# VPAC0_PAR_VPAC_VISS0_S_VBUSP_VISS_FCP_FCC_VBUSP_FLEXCC register map
Vendor: Texas Instruments
Peripheral module from a debugger description file (folder J7ES).
Registers are 32-bit, access per field, reset 0x0 unless marked. A register's access mark holds for its fields unless they carry their own. Offsets are as the file gives them; lines under a group give offsets from that group; [hi:lo] are bit positions; {n}, {i} and the like mark numbered series; 'fields as' and 'values as' point back to an identical list; <NAME> marks a mode.

## VPAC0_PAR_VPAC_VISS0_S_VBUSP_VISS_FCP_FCC_VBUSP_FLEXCC
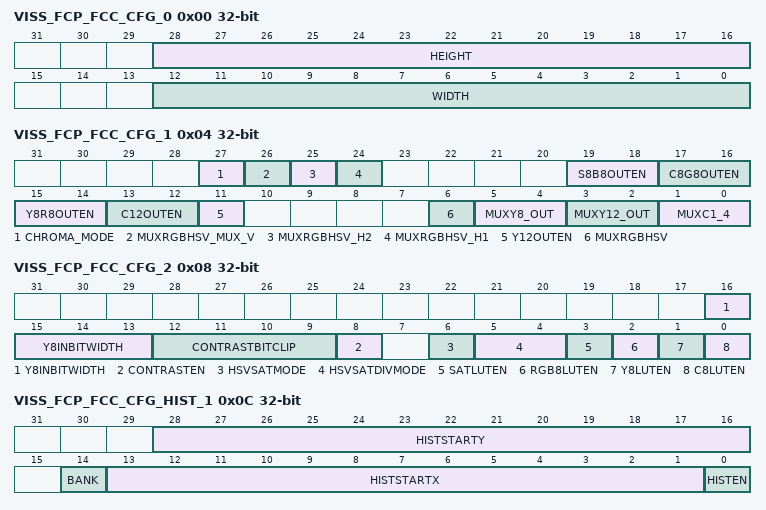
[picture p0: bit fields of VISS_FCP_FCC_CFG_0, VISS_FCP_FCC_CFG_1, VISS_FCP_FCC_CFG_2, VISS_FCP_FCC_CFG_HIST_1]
0x00 VISS_FCP_FCC_CFG_0 — The Control Register controls the input width and height of the module.
  [28:16] HEIGHT rw — Height of the input image
  [12:0] WIDTH rw — Width of the input image
0x04 VISS_FCP_FCC_CFG_1 — Configuration Register for top level data flow
  [27] CHROMA_MODE rw — Mux for 422/420 (
  [26] MUXRGBHSV_MUX_V rw — Mux for V calculation (
  [25] MUXRGBHSV_H2 rw — Mux for S/V calculation (
  [24] MUXRGBHSV_H1 rw — Mux for S/V calculation (
  [19:18] S8B8OUTEN rw — '0': Disable All , '1': S8 enable,
  [17:16] C8G8OUTEN rw — '0': Disable All , '1': C8 enable,
  [15:14] Y8R8OUTEN rw — '0': Disable all , '1': Y8 enable,
  [13:12] C12OUTEN rw — '0': Disable all , '1': C12 enable, '2': C1 enable
  [11] Y12OUTEN rw — '0': Disable Y12 output, '1': Enable Y12 output
  [6] MUXRGBHSV rw — Input Select for RGBHSV (
  [5:4] MUXY8_OUT rw — Mux for Y-8 Output (
  [3:2] MUXY12_OUT rw — Mux for Y-12 Output (
  [1:0] MUXC1_4 rw — Mux for selecting C input (
0x08 VISS_FCP_FCC_CFG_2 — Configuration Register-2
  [16:13] Y8INBITWIDTH rw — Bitwidth of input to 12to8 module (Y8) for shift(Program as 12 or lower)
  [12:9] CONTRASTBITCLIP rw — Clip Value set as 2
  [8] CONTRASTEN rw
  [6] HSVSATMODE rw
  [5:4] HSVSATDIVMODE rw
  [3] SATLUTEN rw — '1':Use LUT, '0':Use shift
  [2] RGB8LUTEN rw — '1':Use LUT, '0':Use shift
  [1] Y8LUTEN rw — '1':Use LUT, '0':Use shift
  [0] C8LUTEN rw — '1':Use LUT, '0':Use shift
0x0C VISS_FCP_FCC_CFG_HIST_1 — Configuration-1 Register for histogram
  [28:16] HISTSTARTY rw — Y Start for Histogram ROI, should be &gt;= 1
  [14] BANK rw — bank select for Histogram
  [13:1] HISTSTARTX rw — X Start for Histogram ROI, should be even
  [0] HISTEN rw — Enable bit for histogram
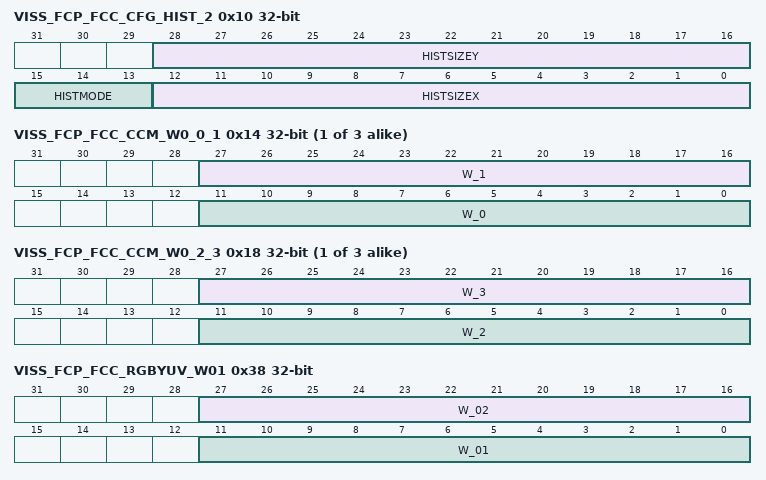
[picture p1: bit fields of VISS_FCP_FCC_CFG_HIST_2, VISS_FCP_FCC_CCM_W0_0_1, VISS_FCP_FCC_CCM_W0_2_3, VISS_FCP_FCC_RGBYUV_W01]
0x10 VISS_FCP_FCC_CFG_HIST_2 — Configuration-2 Register for histogram
  [28:16] HISTSIZEY rw — Y Size (Height) for Histogram ROI
  [15:13] HISTMODE rw — Histogram Mode(0:Col-0(R),1:Col-1(G),2:Col-2(B),3:MuxC1_4,4:R+2G+B/4 )
  [12:0] HISTSIZEX rw — X Size (Width) for Histogram ROI, should be &gt; 256 &amp; even
{0x14+0xC*i} VISS_FCP_FCC_CCM_W{i}_0_1 (i=0..2) — CCM Weights for Row{i}
  [27:16] W_1 rw — Weight W_
  [11:0] W_0 rw — Weight W_
{0x18+0xC*i} VISS_FCP_FCC_CCM_W{i}_2_3 (i=0..2) — CCM Weights for Row{i}
  [27:16] W_3 rw — Weight W_
  [11:0] W_2 rw — Weight W_
{0x1C+0xC*i} VISS_FCP_FCC_CCM_OFFSET_{i} (i=0..2) — CCM OFFSET for Row{i}
  [12:0] OFFSET_{i} rw — OFFSET_
0x38 VISS_FCP_FCC_RGBYUV_W01 — Weight/Offset for Row0
  [27:16] W_02 rw — Weight W_
  [11:0] W_01 rw — Weight W_
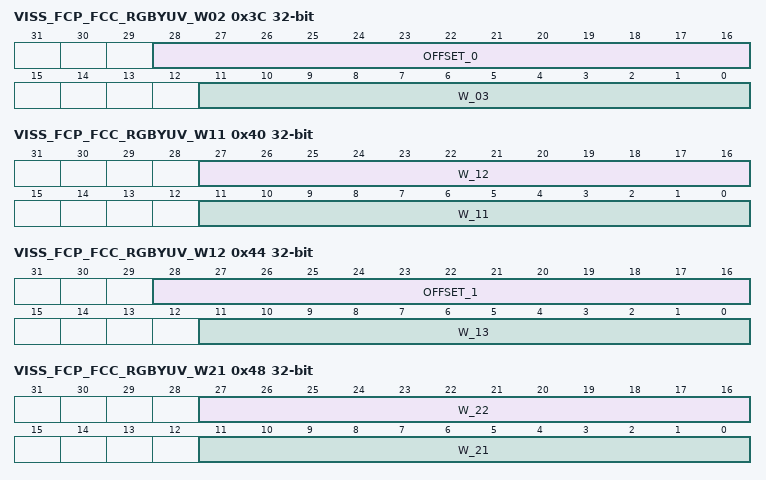
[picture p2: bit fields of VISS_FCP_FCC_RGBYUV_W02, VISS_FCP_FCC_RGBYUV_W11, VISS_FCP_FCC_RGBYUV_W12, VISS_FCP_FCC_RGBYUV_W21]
0x3C VISS_FCP_FCC_RGBYUV_W02 — Weight/Offset for Row0
  [28:16] OFFSET_0 rw — Offset_
  [11:0] W_03 rw — Weight W_
0x40 VISS_FCP_FCC_RGBYUV_W11 — Weight/Offset for Row1
  [27:16] W_12 rw — Weight W_
  [11:0] W_11 rw — Weight W_
0x44 VISS_FCP_FCC_RGBYUV_W12 — Weight/Offset for Row1
  [28:16] OFFSET_1 rw — Offset_
  [11:0] W_13 rw — Weight W_
0x48 VISS_FCP_FCC_RGBYUV_W21 — Weight/Offset for Row2
  [27:16] W_22 rw — Weight W_
  [11:0] W_21 rw — Weight W_
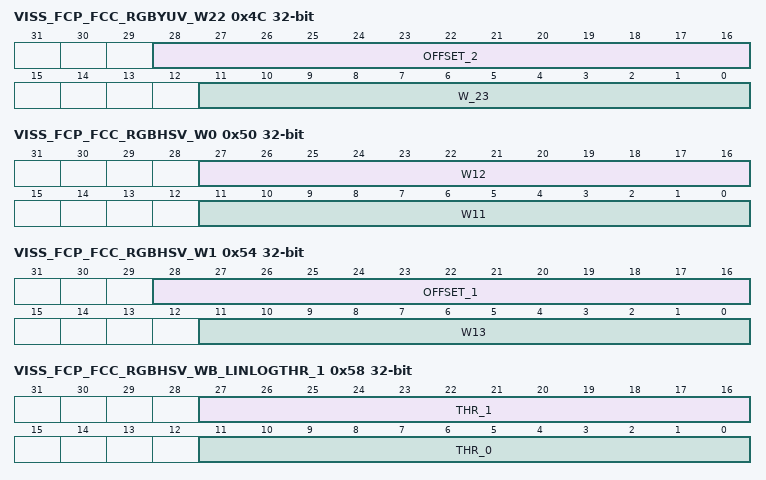
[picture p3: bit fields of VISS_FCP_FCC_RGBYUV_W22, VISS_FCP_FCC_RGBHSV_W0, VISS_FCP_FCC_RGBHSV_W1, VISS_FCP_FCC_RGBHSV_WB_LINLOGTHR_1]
0x4C VISS_FCP_FCC_RGBYUV_W22 — Weight/Offset for Row2
  [28:16] OFFSET_2 rw — Offset_
  [11:0] W_23 rw — Weight W_
0x50 VISS_FCP_FCC_RGBHSV_W0 — Weights 11/12 for V calculation
  [27:16] W12 rw — Weight W12 (Signed 12b)
  [11:0] W11 rw — Weight W11 (Signed 12b)
0x54 VISS_FCP_FCC_RGBHSV_W1 — Weights13 and Offset_1 for V Calculation
  [28:16] OFFSET_1 rw — Offset_1 (Signed 13b)
  [11:0] W13 rw — Weight W13 (Signed 12b)
0x58 VISS_FCP_FCC_RGBHSV_WB_LINLOGTHR_1 — Dynamic WB Thr limit
  [27:16] THR_1 rw — THR_1 / G-Channel Thr (U 12b)
  [11:0] THR_0 rw — THR_0 / R-Channel Thr (U 12b)
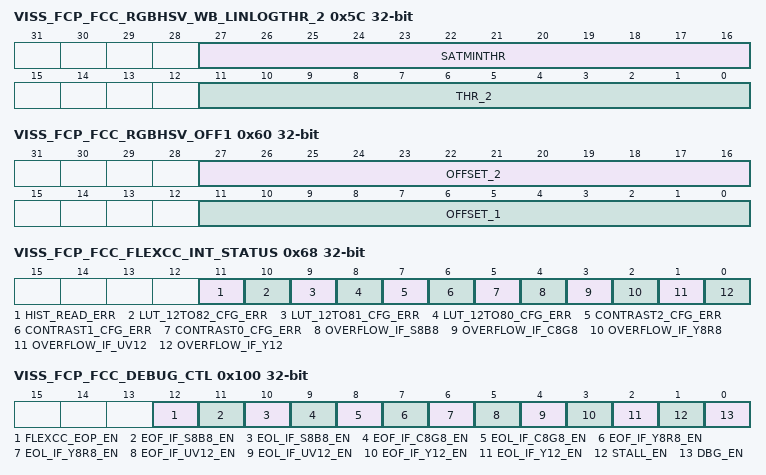
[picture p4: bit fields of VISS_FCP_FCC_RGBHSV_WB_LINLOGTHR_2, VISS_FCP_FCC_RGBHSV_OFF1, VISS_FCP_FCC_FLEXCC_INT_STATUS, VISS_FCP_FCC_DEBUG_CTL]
0x5C VISS_FCP_FCC_RGBHSV_WB_LINLOGTHR_2 — Dynamic WB Thr limit and SatMinThr
  [27:16] SATMINTHR rw — Thr for comparing Min(RGB) limit
  [11:0] THR_2 rw — THR_2 / B-Channel Thr (U 12b)
0x60 VISS_FCP_FCC_RGBHSV_OFF1 — WB Offset for Saturation
  [27:16] OFFSET_2 rw — Offset_2 (U 12b)
  [11:0] OFFSET_1 rw — Offset-1 (U 12b)
0x64 VISS_FCP_FCC_RGBHSV_OFF2 — WB Offsets for Saturation
  [11:0] OFFSET_3 rw — Offset-3 (U 12b)
0x68 VISS_FCP_FCC_FLEXCC_INT_STATUS access not given — Status/clear register for flexcc interrupts
  [11] HIST_READ_ERR — status/clear for histogram memory, set when mem access has occurred to the first location but not to the last location during active frame implying that full histogram was not read . (access RW1C)
  [10] LUT_12TO82_CFG_ERR — status/clear for 12to8_2_lut cfg err, set when mem access occurs during active line when the LUT is enabled causing frame corruption. (access RW1C)
  [9] LUT_12TO81_CFG_ERR — status/clear for 12to8_1_lut cfg err, set when mem access occurs during active line when the LUT is enabled causing frame corruption. (access RW1C)
  [8] LUT_12TO80_CFG_ERR — status/clear for 12to8_0_lut cfg err, set when mem access occurs during active line when the LUT is enabled causing frame corruption. (access RW1C)
  [7] CONTRAST2_CFG_ERR — status/clear for contrast2_lut cfg err, set when mem access occurs during active line when the LUT is enabled causing frame corruption. (access RW1C)
  [6] CONTRAST1_CFG_ERR — status/clear for contrast1_lut cfg err, set when mem access occurs during active line when the LUT is enabled causing frame corruption. (access RW1C)
  [5] CONTRAST0_CFG_ERR — status/clear for contrast0_lut cfg err, set when mem access occurs during active line when the LUT is enabled causing frame corruption. (access RW1C)
  [4] OVERFLOW_IF_S8B8 — status/clear for overflow on s8b8 i/f, set when fifo overflows causing frame corruption. (access RW1C)
  [3] OVERFLOW_IF_C8G8 — status/clear for overflow on c8g8 i/f, set when fifo overflows causing frame corruption. (access RW1C)
  [2] OVERFLOW_IF_Y8R8 — status/clear for overflow on y8r8 i/f, set when fifo overflows causing frame corruption. (access RW1C)
  [1] OVERFLOW_IF_UV12 — status/clear for overflow on uv12 i/f, set when fifo overflows causing frame corruption. (access RW1C)
  [0] OVERFLOW_IF_Y12 — status/clear for overflow on y12 i/f, set when fifo overflows causing frame corruption. (access RW1C)
0x100 VISS_FCP_FCC_DEBUG_CTL — Enable for different debug events
  [12] FLEXCC_EOP_EN rw — Enable for flexcc eop
  [11] EOF_IF_S8B8_EN rw — Enable for eof on s8b8
  [10] EOL_IF_S8B8_EN rw — Enable for eol on s8b8
  [9] EOF_IF_C8G8_EN rw — Enable for eof on c8g8
  [8] EOL_IF_C8G8_EN rw — Enable for eol on c8g8
  [7] EOF_IF_Y8R8_EN rw — Enable for eof on y8r8
  [6] EOL_IF_Y8R8_EN rw — Enable for eol on y8r8
  [5] EOF_IF_UV12_EN rw — Enable for eof on uv12
  [4] EOL_IF_UV12_EN rw — Enable for eol on uv12
  [3] EOF_IF_Y12_EN rw — Enable for eof on y12
  [2] EOL_IF_Y12_EN rw — Enable for eol on y12
  [1] STALL_EN rw — Enable for stall event
  [0] DBG_EN rw — Enable debug features, set to '0' to disable all debug events
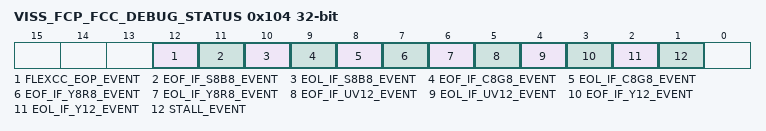
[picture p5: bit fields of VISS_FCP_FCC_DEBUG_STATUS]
0x104 VISS_FCP_FCC_DEBUG_STATUS access not given — Set/Clear for debug events
  [12] FLEXCC_EOP_EVENT — Status/Clear for flexcc eop, write '1' to clear (access RW1C)
  [11] EOF_IF_S8B8_EVENT — Status/Clear for eof on s8b8, write '1' to clear (access RW1C)
  [10] EOL_IF_S8B8_EVENT — Status/Clear for eol on s8b8, write '1' to clear (access RW1C)
  [9] EOF_IF_C8G8_EVENT — Status/Clear for eof on c8g8, write '1' to clear (access RW1C)
  [8] EOL_IF_C8G8_EVENT — Status/Clear for eol on c8g8, write '1' to clear (access RW1C)
  [7] EOF_IF_Y8R8_EVENT — Status/Clear for eof on y8r8, write '1' to clear (access RW1C)
  [6] EOL_IF_Y8R8_EVENT — Status/Clear for eol on y8r8, write '1' to clear (access RW1C)
  [5] EOF_IF_UV12_EVENT — Status/Clear for eof on uv12, write '1' to clear (access RW1C)
  [4] EOL_IF_UV12_EVENT — Status/Clear for eol on uv12, write '1' to clear (access RW1C)
  [3] EOF_IF_Y12_EVENT — Status/Clear for eof on y12, write '1' to clear (access RW1C)
  [2] EOL_IF_Y12_EVENT — Status/Clear for eol on y12, write '1' to clear (access RW1C)
  [1] STALL_EVENT — Status/Clear for stall event, write '1' to clear (access RW1C)
0x108 VISS_FCP_FCC_DEBUG_RAW rw — Set/Clear for debug RAW mode
  [0] DBG_RAW_MODE — Enable debug RAW mode, takes input from RAWFE and delivers to FlexCC as C
